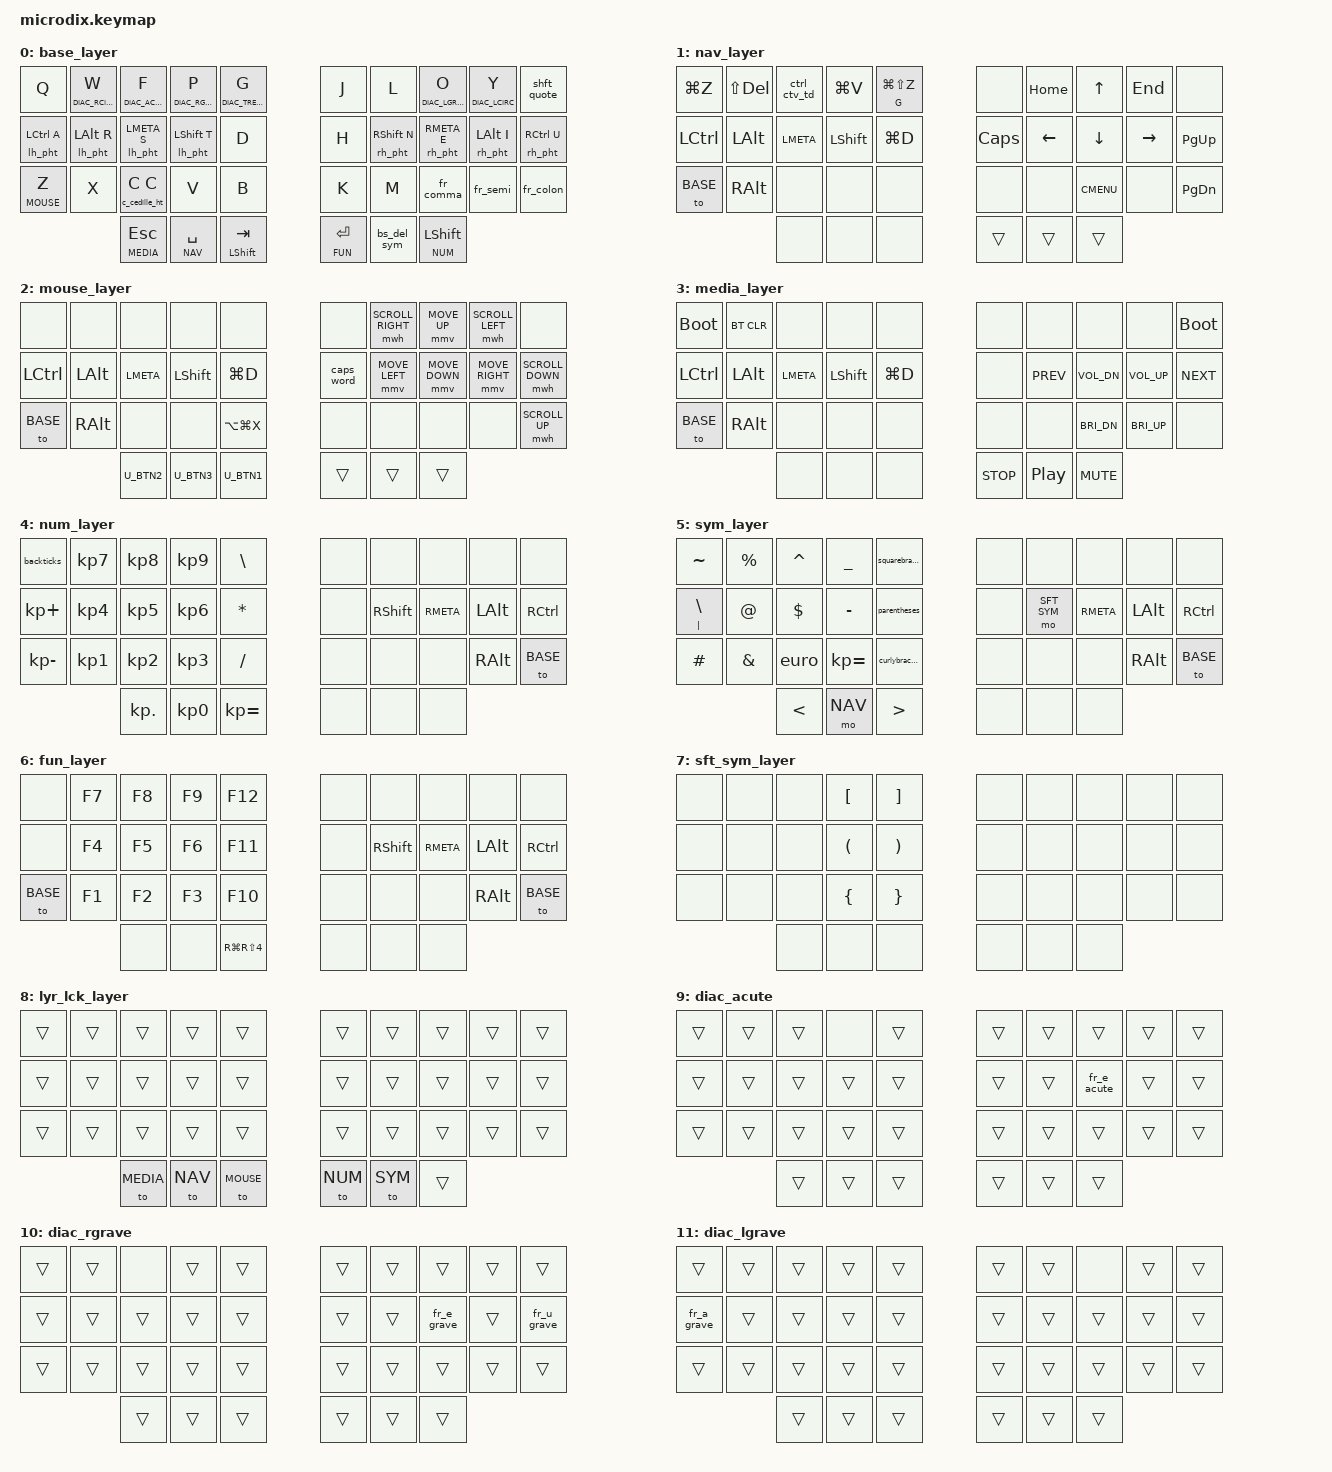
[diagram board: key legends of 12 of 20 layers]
/*
 * Copyright (c) 2020 The ZMK Contributors
 *
 * SPDX-License-Identifier: MIT
 */
#define HOST_OS 2
#include <behaviors.dtsi>
#include <dt-bindings/zmk/keys.h>
#include <dt-bindings/zmk/bt.h>
#include <dt-bindings/zmk/mouse.h>
#include <dt-bindings/zmk/mouse_settings.h>
// Enable Mouse Keys
#include "helper/mouse_keys.dtsi"
#include "../../../../zmk-nodefree-config/helper.h"
#include "../../../../zmk-nodefree-config/keypos_def/keypos_36keys.h"
#include "../../../../zmk-nodefree-config/international_chars/french.dtsi"

#define BASE       0
#define NAV        1
#define MOUSE      2
#define MEDIA      3
#define NUM        4
#define SYM        5
#define FUN        6
#define SFT_SYM    7
#define LYR_LCK    8
#define DIAC_ACUTE 9
#define DIAC_RGRAVE 10
#define DIAC_LGRAVE 11
#define DIAC_RCIRC 12
#define DIAC_LCIRC 13
#define DIAC_TREMA 14
#define SMART_CASE 15
#define CAMEL_CASE 16
#define SNAKE_CASE 17
#define KEBAB_CASE 18
#define MOUSE_SET 19

#define KEYS_L LT0 LT1 LT2 LT3 LT4 LM0 LM1 LM2 LM3 LM4 LB0 LB1 LB2 LB3 LB4  // left-hand keys
#define KEYS_R RT0 RT1 RT2 RT3 RT4 RM0 RM1 RM2 RM3 RM4 RB0 RB1 RB2 RB3 RB4  // right-hand keys
#define THUMBS LH2 LH1 LH0 RH0 RH1 RH2                                      // thumb keys

#define ______ &trans
#define xxxxxx &none

#undef COMBO_TERM
#define COMBO_TERM 50

#define QUICK_TAP_MS 175

&mt {
    tapping-term-ms = <175>;
    flavor = "tap-preferred";
};

&sk {
     release-after-ms = <2000>;
     quick-release;
     ignore-modifiers;
};

&caps_word {
    continue-list = <UNDERSCORE MINUS BACKSPACE M>;
};

// middle dot
ZMK_UNICODE_SINGLE(middle_dot, N0, N0, B, N7)

// euro
ZMK_UNICODE_SINGLE(euro, N2, N0, A, C)

// open / close brackets
ZMK_BEHAVIOR(parentheses, macro,
	wait-ms = <0>;
	tap-ms = <5>;
	bindings = <&kp LPAR>, <&kp RPAR>, <&kp LEFT_ARROW>;
)
ZMK_BEHAVIOR(squarebrackets, macro,
	wait-ms = <0>;
	tap-ms = <5>;
	bindings = <&kp LBKT>, <&kp RBKT>, <&kp LEFT_ARROW>;
)
ZMK_BEHAVIOR(curlybrackets, macro,
	wait-ms = <0>;
	tap-ms = <5>;
	bindings = <&kp LBRC>, <&kp RBRC>, <&kp LEFT_ARROW>;
)
ZMK_BEHAVIOR(backticks, macro,
	wait-ms = <0>;
	tap-ms = <5>;
	bindings = <&kp GRAVE>, <&kp GRAVE>, <&kp LEFT_ARROW>;
)

// tap -> c | hold -> ç | hold + shift -> Ç
ZMK_BEHAVIOR(c_cedille_ht, hold_tap,
	flavor = "tap-preferred";
	tapping-term-ms = <175>;
	bindings = <&fr_c_cedilla>, <&kp>;
)

// mouse settings toggle
ZMK_COMBO(mouse_settings, &tog MOUSE_SET, LT3 LT2 LT1, BASE)

// y + ' -> !
ZMK_COMBO(combo_exlm, &kp EXCL, RT3 RT4, BASE)

// , + ; -> middle dot
ZMK_COMBO(combo_middle_dot, &middle_dot, RB2 RB3, BASE)

// combo fun layer
ZMK_COMBO(combo_fun_layer, &mo FUN, LH0 RH0, BASE)

// combo smart case
ZMK_COMBO(combo_smart_layer, &mo SMART_CASE, LH2 RH2, BASE)

// combo scroll lock (compose key)
ZMK_COMBO(combo_compose_key, &kp SCROLLLOCK, LB2 LB1, BASE)

// tap -> ', shift tap -> "
ZMK_BEHAVIOR(shft_quote, mod_morph,
	bindings = <&kp SQT>, <&kp DQT>;
	mods = <(MOD_LSFT|MOD_RSFT)>;
)

// tap -> ",", shift tap -> "?"
ZMK_BEHAVIOR(fr_comma, mod_morph,
	bindings = <&kp COMMA>, <&kp QMARK>;
	mods = <(MOD_LSFT|MOD_RSFT)>;
)

// tap -> ";", shift tap -> "."
ZMK_BEHAVIOR(fr_semi, mod_morph,
	bindings = <&kp SEMI>, <&kp DOT>;
	mods = <(MOD_LSFT|MOD_RSFT)>;
)

// tap -> ":", shift tap -> "/"
ZMK_BEHAVIOR(fr_colon, mod_morph,
	bindings = <&kp COLON>, <&kp SLASH>;
	mods = <(MOD_LSFT|MOD_RSFT)>;
)

// tap -> copy | double-tap -> copy + ctrl+f | triple-tap -> copy + ctrl+t, ctrl+v, enter
ZMK_BEHAVIOR(ctrl_ctv_td, tap_dance,
	tapping-term-ms = <175>;
	bindings = <&kp LG(C)>, <&kp LG(F)>, <&ctrl_c_t_v>;
)
ZMK_BEHAVIOR(ctrl_c_t_v, macro,
	wait-ms = <0>;
	tap-ms = <100>;
	bindings = <&kp LG(C)>, <&kp LG(T)>, <&kp LG(V)>, <&kp ENTER>;
)

// tap -> backspace | rshft + tap: delete | hold: sym layer
ZMK_BEHAVIOR(bs_del_sym, mod_morph,
    bindings = <&lt SYM BSPC>, <&kp DEL>;
    mods = <(MOD_RSFT)>;
)

// home-row mods
ZMK_BEHAVIOR(lh_pht, hold_tap,  // left-hand HRMs
	flavor = "balanced";
	tapping-term-ms = <180>;
	quick-tap-ms = <QUICK_TAP_MS>;
	bindings = <&kp>, <&kp>;
	hold-trigger-key-positions = <KEYS_R THUMBS>;
	hold-trigger-on-release;            // requires PR #1423
)
ZMK_BEHAVIOR(rh_pht, hold_tap,  // right-hand HRMs
	flavor = "balanced";
	tapping-term-ms = <180>;
	quick-tap-ms = <QUICK_TAP_MS>;
	bindings = <&kp>, <&kp>;
	hold-trigger-key-positions = <KEYS_L THUMBS>;
	hold-trigger-on-release;            // requires PR #1423
)

/* keymap */

ZMK_LAYER(base_layer,
	&kp Q				&lt DIAC_RCIRC W	&lt DIAC_ACUTE F		&lt DIAC_RGRAVE P	&lt DIAC_TREMA G			&kp J			&kp L				&lt DIAC_LGRAVE O	&lt DIAC_LCIRC Y	&shft_quote
	&lh_pht LCTRL A		&lh_pht LALT R		&lh_pht LMETA S			&lh_pht LSHFT T		&kp D 						&kp H			&rh_pht RSHFT N		&rh_pht RMETA E		&rh_pht LALT I		&rh_pht RCTRL U
	&lt MOUSE Z			&kp X				&c_cedille_ht C C		&kp V				&kp B 						&kp K			&kp M 				&fr_comma			&fr_semi        	&fr_colon
											&lt MEDIA ESC 			&lt NAV SPACE		&mt LSHFT TAB				&lt FUN ENTER	&bs_del_sym			&lt NUM LSHFT
)
ZMK_LAYER(nav_layer,
	&kp LG(Z)	&kp LS(DEL)		&ctrl_ctv_td	&kp LG(V)		&mt G LG(LS(Z))				xxxxxx				&kp HOME			&kp UP_ARROW		&kp END				xxxxxx
	&kp LCTRL 	&kp LALT		&kp LMETA 		&kp LSHFT 		&kp LG(D) 				&kp CAPSLOCK		&kp LEFT_ARROW		&kp DOWN_ARROW		&kp RIGHT_ARROW		&kp PG_UP
	&to BASE	&kp RALT		xxxxxx			xxxxxx			xxxxxx	 					xxxxxx				xxxxxx	 			&kp K_CMENU			xxxxxx				&kp PG_DN
								xxxxxx 			xxxxxx			xxxxxx						______				______				______
)
ZMK_LAYER(mouse_layer,
	xxxxxx			xxxxxx			xxxxxx			xxxxxx			xxxxxx						xxxxxx			&mwh SCROLL_RIGHT	&mmv MOVE_UP		&mwh SCROLL_LEFT		xxxxxx
	&kp LCTRL 		&kp LALT		&kp LMETA 		&kp LSHFT 		&kp LG(D) 					&caps_word		&mmv MOVE_LEFT	 	&mmv MOVE_DOWN		&mmv MOVE_RIGHT			&mwh SCROLL_DOWN
	&to BASE		&kp RALT		xxxxxx			xxxxxx			&kp LA(LG(X))				xxxxxx			xxxxxx	 			xxxxxx				xxxxxx					&mwh SCROLL_UP
									U_BTN2 			U_BTN3			U_BTN1						______			______				______
)
ZMK_LAYER(media_layer,
	&bootloader		&bt BT_CLR		xxxxxx			xxxxxx			xxxxxx				xxxxxx			xxxxxx			xxxxxx				xxxxxx				&bootloader
	&kp LCTRL 		&kp LALT		&kp LMETA 		&kp LSHFT 		&kp LG(D) 			xxxxxx			&kp C_PREV		&kp C_VOL_DN		&kp C_VOL_UP		&kp C_NEXT
	&to BASE		&kp RALT		xxxxxx			xxxxxx			xxxxxx	 			xxxxxx			xxxxxx			&kp C_BRI_DN		&kp C_BRI_UP		xxxxxx
									xxxxxx 			xxxxxx			xxxxxx				&kp C_STOP		&kp C_PP		&kp C_MUTE
)
ZMK_LAYER(num_layer,
	&backticks		&kp KP_N7		&kp KP_N8		&kp KP_N9		&kp BSLH				xxxxxx				xxxxxx			xxxxxx			xxxxxx			xxxxxx
	&kp KP_PLUS		&kp KP_N4		&kp KP_N5 		&kp KP_N6 		&kp ASTRK	 			xxxxxx				&kp RSHFT		&kp RMETA		&kp LALT		&kp RCTRL
	&kp KP_MINUS	&kp KP_N1		&kp KP_N2		&kp KP_N3		&kp SLASH				xxxxxx				xxxxxx			xxxxxx			&kp RALT		&to BASE
									&kp KP_DOT		&kp KP_N0		&kp KP_EQUAL			xxxxxx				xxxxxx			xxxxxx
)
ZMK_LAYER(sym_layer,
	&kp TILDE				&kp PERCENT		&kp CARET		&kp UNDER		&squarebrackets			xxxxxx				xxxxxx			xxxxxx			xxxxxx			xxxxxx
	&mt PIPE BACKSLASH		&kp AT_SIGN		&kp DLLR 		&kp MINUS		&parentheses			xxxxxx				&mo SFT_SYM		&kp RMETA		&kp LALT		&kp RCTRL
	&kp HASH				&kp AMPS		&euro			&kp KP_EQUAL	&curlybrackets			xxxxxx				xxxxxx			xxxxxx			&kp RALT		&to BASE
											&kp LT			&mo NAV			&kp GT					xxxxxx				xxxxxx			xxxxxx
)
ZMK_LAYER(fun_layer,
	xxxxxx		&kp F7		&kp F8		&kp F9		&kp F12			    xxxxxx			xxxxxx			xxxxxx			xxxxxx			xxxxxx
	xxxxxx		&kp F4		&kp F5		&kp F6		&kp F11		    	xxxxxx			&kp RSHFT		&kp RMETA		&kp LALT		&kp RCTRL
	&to BASE	&kp F1		&kp F2		&kp F3		&kp F10		    	xxxxxx			xxxxxx			xxxxxx			&kp RALT		&to BASE
							xxxxxx		xxxxxx		&kp RG(RS(N4))		xxxxxx			xxxxxx			xxxxxx
)
ZMK_LAYER(sft_sym_layer,
	xxxxxx		xxxxxx		xxxxxx		&kp LBKT		&kp RBKT				xxxxxx		xxxxxx		xxxxxx		xxxxxx		xxxxxx
	xxxxxx		xxxxxx		xxxxxx		&kp LPAR		&kp RPAR				xxxxxx		xxxxxx		xxxxxx		xxxxxx		xxxxxx
	xxxxxx		xxxxxx		xxxxxx		&kp LBRC		&kp RBRC				xxxxxx		xxxxxx		xxxxxx		xxxxxx		xxxxxx
							xxxxxx		xxxxxx			xxxxxx					xxxxxx		xxxxxx		xxxxxx
)
ZMK_LAYER(lyr_lck_layer,
	______		______		______			______		______					______		______		______		______		______
	______		______		______			______		______					______		______		______		______		______
	______		______		______			______		______					______		______		______		______		______
							&to MEDIA 		&to NAV		&to MOUSE 				&to NUM		&to SYM		______
)
ZMK_LAYER(diac_acute,
	______		______		______		xxxxxx		______				______		______		______			______		______
	______		______		______		______		______				______		______		&fr_e_acute		______		______
	______		______		______		______		______				______		______		______			______		______
							______ 		______		______ 				______		______		______
)
ZMK_LAYER(diac_rgrave,
	______		______		xxxxxx		______		______				______		______		______			______		______
	______		______		______		______		______				______		______		&fr_e_grave		______		&fr_u_grave
	______		______		______		______		______				______		______		______			______		______
							______ 		______		______ 				______		______		______
)
ZMK_LAYER(diac_lgrave,
	______			______		______		______		______				______		______		xxxxxx		______		______
	&fr_a_grave		______		______		______		______				______		______		______		______		______
	______			______		______		______		______				______		______		______		______		______
								______ 		______		______ 				______		______		______
)
ZMK_LAYER(diac_rcirc,
	______		xxxxxx		______			______		______				______		______		&fr_o_circumflex	______				______
	______		______		______			______		______				______		______		&fr_e_circumflex	&fr_i_circumflex	&fr_u_circumflex
	______		______		______			______		______				______		______		______				______				______
							______ 			______		______ 				______		______		______
)
ZMK_LAYER(diac_lcirc,
	______				______		______		______		______				______		______		______		xxxxxx		______
	&fr_a_circumflex	______		______		______		______				______		______		______		______		______
	______				______		______		______		______				______		______		______		______		______
									______ 		______		______ 				______		______		______
)
ZMK_LAYER(diac_trema,
	______		______		______		______		xxxxxx				______		______		______				&fr_y_diaeresis		______
	______		______		______		______		______				______		______		&fr_e_diaeresis		&fr_i_diaeresis		&fr_u_diaeresis
	______		______		______		______		______				______		______		______				______				______
							______ 		______		______ 				______		______		______
)
ZMK_LAYER(smart_case,
	______		______				______		______		______				______				______		______		______		______
	______		______		&tog SNAKE_CASE		______		______				______				______		______		______		______
	______		______		&tog CAMEL_CASE		______		______				&tog KEBAB_CASE		______		______		______		______
									______ 		______		______ 				______				______		______
)
ZMK_LAYER(camel_case,
	______		______		______				______		______				______		______		______		______		______
	______		______		______				______		______				______		______		______		______		______
	______		______		______				______		______				______		______		______		______		______
							&tog CAMEL_CASE		&sk LSHFT	______ 				______		______		______
)
ZMK_LAYER(snake_case,
	______		______		______				______		______				______		______		______		______		______
	______		______		______				______		______				______		______		______		______		______
	______		______		______				______		______				______		______		______		______		______
							&tog SNAKE_CASE		&kp UNDER	______ 				______		______		______
)
ZMK_LAYER(kebab_case,
	______		______		______				______		______				______		______		______		______		______
	______		______		______				______		______				______		______		______		______		______
	______		______		______				______		______				______		______		______		______		______
							&tog KEBAB_CASE		&kp MINUS	______ 				______		______		______
)

ZMK_LAYER(mouse_settings,
// ╭────────────────────────┬────────────────────────┬────────────────────────┬────────────────────────┬────────────────────────╮    ╭────────────────────────┬────────────────────────┬────────────────────────┬────────────────────────┬────────────────────────╮
     &none                    &none                    U_MSS_TP_S_D             U_MSS_TP_S_I             U_MSS_TP_PT_I                 &none                    &none                    &none                    &none                    &none
// ├────────────────────────┼────────────────────────┼────────────────────────┼────────────────────────┼────────────────────────┤    ├────────────────────────┼────────────────────────┼────────────────────────┼────────────────────────┼────────────────────────┤
     &none                    &none                    U_MSS_TP_NI_D            U_MSS_TP_NI_I            U_MSS_TP_PT_D                 &none                    &none                    &none                    &none                    &none
// ├────────────────────────┼────────────────────────┼────────────────────────┼────────────────────────┼────────────────────────┤    ├────────────────────────┼────────────────────────┼────────────────────────┼────────────────────────┼────────────────────────┤
     &none                    &none                    U_MSS_TP_V6_D            U_MSS_TP_V6_I            &none                         &none                    &none                    &none                    &none                    &none
// ╰────────────────────────┴────────────────────────┴────────────────────────┼────────────────────────┼────────────────────────┤    ├────────────────────────┼────────────────────────┼────────────────────────┼────────────────────────┴────────────────────────╯
                                                       &tog MOUSE_SET           U_BTN1                   U_BTN2                        U_BTN3                   U_BTN1                   U_BTN2
//                                                   ╰────────────────────────┴────────────────────────┴────────────────────────╯    ╰────────────────────────┴────────────────────────┴────────────────────────╯
)
